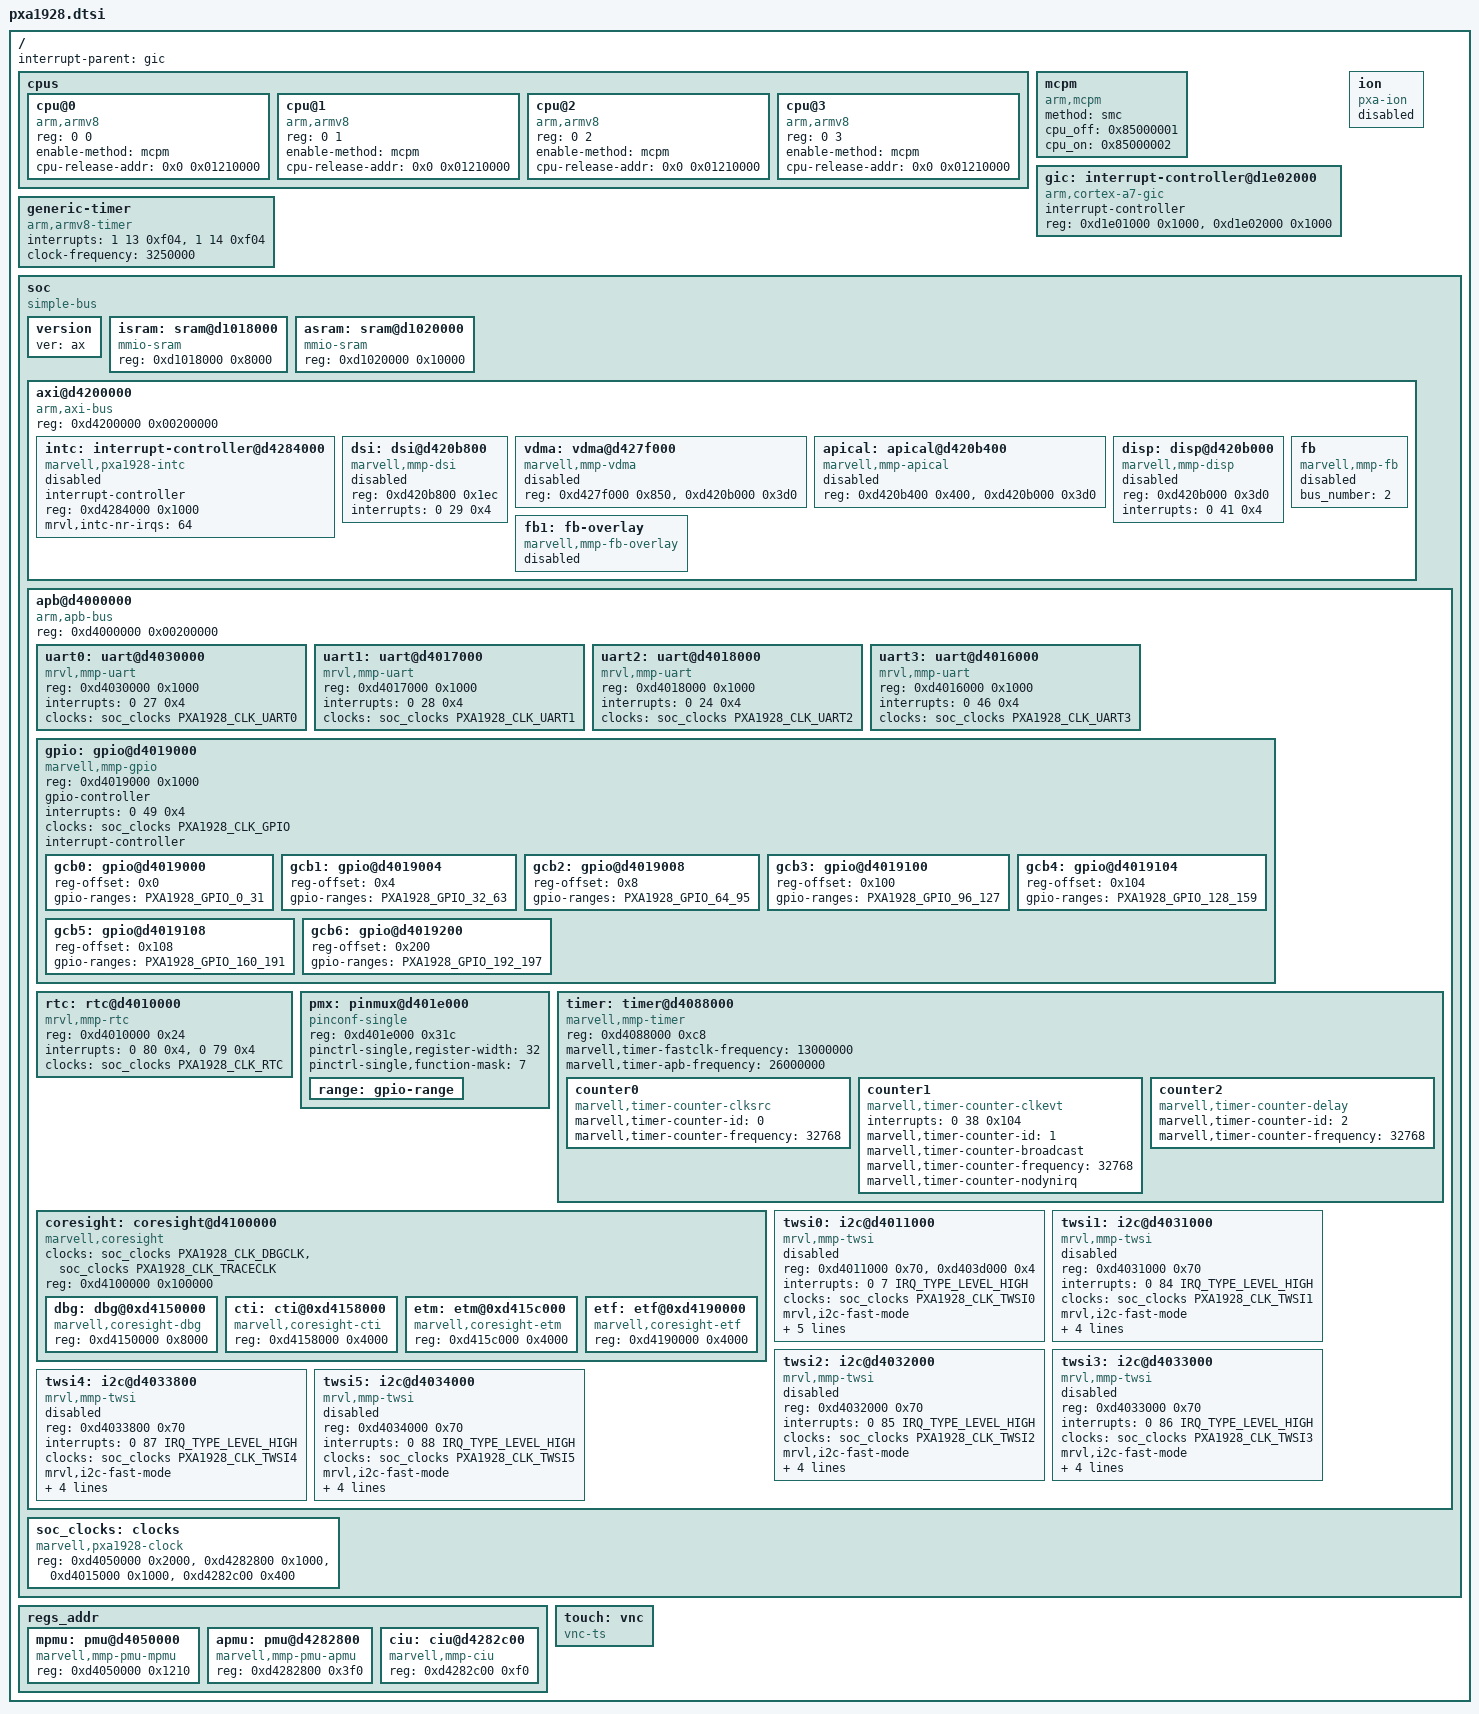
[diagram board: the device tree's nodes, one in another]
/*
 *  Copyright (C) 2013 Marvell Technology Group Ltd.
 *  Author: Chao Xie <chao.xie@marvell.com>
 *
 *  This program is free software; you can redistribute it and/or modify
 *  it under the terms of the GNU General Public License version 2 as
 *  publishhed by the Free Software Foundation.
 */
/memreserve/ 0x01210000 0x8;
#include "pxa1928-pinfunc.h"
#include "../../../../include/dt-bindings/clock/marvell-pxa1928.h"
#include "../../../../include/dt-bindings/interrupt-controller/irq.h"

/ {
	interrupt-parent = <&gic>;
	#address-cells = <1>;
	#size-cells = <1>;

	cpus {
		#address-cells = <2>;
		#size-cells = <0>;

		cpu@0 {
			device_type = "cpu";
			compatible = "arm,armv8";
			reg = <0 0>;
			enable-method = "mcpm";
			cpu-release-addr = <0x0 0x01210000>;
		};
		cpu@1 {
			device_type = "cpu";
			compatible = "arm,armv8";
			reg = <0 1>;
			enable-method = "mcpm";
			cpu-release-addr = <0x0 0x01210000>;
		};
		cpu@2 {
			device_type = "cpu";
			compatible = "arm,armv8";
			reg = <0 2>;
			enable-method = "mcpm";
			cpu-release-addr = <0x0 0x01210000>;
		};
		cpu@3 {
			device_type = "cpu";
			compatible = "arm,armv8";
			reg = <0 3>;
			enable-method = "mcpm";
			cpu-release-addr = <0x0 0x01210000>;
		};
	};

    mcpm {
		compatible      = "arm,mcpm";
		method          = "smc";
		cpu_off		= <0x85000001>;
		cpu_on		= <0x85000002>;
	};

	gic: interrupt-controller@d1e02000 {
		compatible = "arm,cortex-a7-gic";
		interrupt-controller;
		#interrupt-cells = <3>;
		reg = <0xd1e01000 0x1000>,
		      <0xd1e02000 0x1000>;
	};

	generic-timer {
		compatible = "arm,armv8-timer";
		interrupts = <1 13 0xf04>,
		             <1 14 0xf04>;
		clock-frequency = <3250000>;
	};

	ion: ion {
		compatible = "pxa-ion";
		#stream-id-cells = <1>;
		status = "disabled";
	};

	soc {
		#address-cells = <1>;
		#size-cells = <1>;
		compatible = "simple-bus";
		ranges;

		version {
			ver = "ax";
		};

		isram: sram@d1018000 {
			compatible = "mmio-sram";
			reg = <0xd1018000 0x8000>;	/* 32KB */
		};

		asram: sram@d1020000 {
			compatible = "mmio-sram";
			reg = <0xd1020000 0x10000>;	/* 64KB */
		};

		axi@d4200000 {	/* AXI */
			compatible = "arm,axi-bus", "simple-bus";
			#address-cells = <1>;
			#size-cells = <1>;
			reg = <0xd4200000 0x00200000>;
			ranges;

			intc: interrupt-controller@d4284000 {
				compatible = "marvell,pxa1928-intc";
				interrupt-controller;
				#interrupt-cells = <1>;
				reg = <0xd4284000 0x1000>;
				mrvl,intc-nr-irqs = <64>;
				status = "disabled";
			};
			dsi: dsi@d420b800 {
				compatible = "marvell,mmp-dsi";
				reg = <0xd420b800 0x1ec>;
				interrupts = <0 29 0x4>;
				status = "disabled";
			};

			vdma: vdma@d427f000 {
				compatible = "marvell,mmp-vdma";
				reg = <0xd427f000 0x850>, <0xd420b000 0x3d0>;
				status = "disabled";
			};

			apical: apical@d420b400 {
				compatible = "marvell,mmp-apical";
				reg = <0xd420b400 0x400>, <0xd420b000 0x3d0>;
				status = "disabled";
			};

			disp: disp@d420b000 {
				compatible = "marvell,mmp-disp";
				reg = <0xd420b000 0x3d0>;
				interrupts = <0 41 0x4>;
				status = "disabled";
			};

			fb: fb {
				bus_number = <2>;
				compatible = "marvell,mmp-fb";
				status = "disabled";
			};

			fb1: fb-overlay {
				compatible = "marvell,mmp-fb-overlay";
				status = "disabled";
			};
		};

		apb@d4000000 {	/* APB */
			compatible = "arm,apb-bus", "simple-bus";
			#address-cells = <1>;
			#size-cells = <1>;
			reg = <0xd4000000 0x00200000>;
			ranges;

			uart0: uart@d4030000 {
				compatible = "mrvl,mmp-uart";
				reg = <0xd4030000 0x1000>;
				interrupts = <0 27 0x4>;
				clocks = <&soc_clocks PXA1928_CLK_UART0>;
			};

			uart1: uart@d4017000 {
				compatible = "mrvl,mmp-uart";
				reg = <0xd4017000 0x1000>;
				interrupts = <0 28 0x4>;
				clocks = <&soc_clocks PXA1928_CLK_UART1>;
			};

			uart2: uart@d4018000 {
				compatible = "mrvl,mmp-uart";
				reg = <0xd4018000 0x1000>;
				interrupts = <0 24 0x4>;
				clocks = <&soc_clocks PXA1928_CLK_UART2>;
			};

			uart3: uart@d4016000 {
				compatible = "mrvl,mmp-uart";
				reg = <0xd4016000 0x1000>;
				interrupts = <0 46 0x4>;
				clocks = <&soc_clocks PXA1928_CLK_UART3>;
			};

			gpio: gpio@d4019000 {
				compatible = "marvell,mmp-gpio";
				#address-cells = <1>;
				#size-cells = <1>;
				reg = <0xd4019000 0x1000>;
				gpio-controller;
				#gpio-cells = <2>;
				interrupts = <0 49 0x4>;
				clocks = <&soc_clocks PXA1928_CLK_GPIO>;
				interrupt-names = "gpio_mux";
				interrupt-controller;
				#interrupt-cells = <2>;
				ranges;

				gcb0: gpio@d4019000 {
					reg-offset = <0x0>;
					gpio-ranges = <PXA1928_GPIO_0_31>;
				};

				gcb1: gpio@d4019004 {
					reg-offset = <0x4>;
					gpio-ranges = <PXA1928_GPIO_32_63>;
				};

				gcb2: gpio@d4019008 {
					reg-offset = <0x8>;
					gpio-ranges = <PXA1928_GPIO_64_95>;
				};

				gcb3: gpio@d4019100 {
					reg-offset = <0x100>;
					gpio-ranges = <PXA1928_GPIO_96_127>;
				};

				gcb4: gpio@d4019104 {
					reg-offset = <0x104>;
					gpio-ranges = <PXA1928_GPIO_128_159>;
				};

				gcb5: gpio@d4019108 {
					reg-offset = <0x108>;
					gpio-ranges = <PXA1928_GPIO_160_191>;
				};

				gcb6: gpio@d4019200 {
					reg-offset = <0x200>;
					gpio-ranges = <PXA1928_GPIO_192_197>;
				};
			};

			rtc: rtc@d4010000 {
				compatible = "mrvl,mmp-rtc";
				reg = <0xd4010000 0x24>;
				interrupts = <0 80 0x4>,<0 79 0x4>;
				interrupt-names = "rtc 1Hz", "rtc alarm";
				clocks = <&soc_clocks PXA1928_CLK_RTC>;
			};

			pmx: pinmux@d401e000 {
				compatible = "pinconf-single";
				reg = <0xd401e000 0x31c>;
				#address-cells = <1>;
				#size-cells = <1>;
				#gpio-range-cells = <3>;
				ranges;

				pinctrl-single,register-width = <32>;
				pinctrl-single,function-mask = <7>;

				range: gpio-range {
					#pinctrl-single,gpio-range-cells = <3>;
				};
			};

			timer: timer@d4088000 {
				compatible = "marvell,mmp-timer";
				reg = <0xd4088000 0xc8>;
				marvell,timer-fastclk-frequency = <13000000>;
				marvell,timer-apb-frequency = <26000000>;

				counter0 {
					compatible = "marvell,timer-counter-clksrc";
					marvell,timer-counter-id = <0>;
					marvell,timer-counter-frequency = <32768>;
				};

				counter1 {
					compatible = "marvell,timer-counter-clkevt";
					interrupts = <0 38 0x104>;
					marvell,timer-counter-id = <1>;
					marvell,timer-counter-broadcast;
					marvell,timer-counter-frequency = <32768>;
					marvell,timer-counter-nodynirq;
				};

				counter2 {
					compatible = "marvell,timer-counter-delay";
					marvell,timer-counter-id = <2>;
					marvell,timer-counter-frequency = <32768>;
				};
			};

			coresight: coresight@d4100000 {
				compatible = "marvell,coresight";
				clocks = <&soc_clocks PXA1928_CLK_DBGCLK>,
					 <&soc_clocks PXA1928_CLK_TRACECLK>;
				clock-names = "DBGCLK","TRACECLK";
				#address-cells = <1>;
				#size-cells = <1>;
				reg = <0xd4100000 0x100000>;
				ranges;

				dbg: dbg@0xd4150000 {
					compatible = "marvell,coresight-dbg";
					reg = <0xd4150000 0x8000>;
				};

				cti: cti@0xd4158000 {
					compatible = "marvell,coresight-cti";
				        reg = <0xd4158000 0x4000>;
				};

				etm: etm@0xd415c000 {
					compatible = "marvell,coresight-etm";
				        reg = <0xd415c000 0x4000>;
				};

				etf: etf@0xd4190000 {
					compatible = "marvell,coresight-etf";
				        reg = <0xd4190000 0x4000>;
				};
			};

			twsi0: i2c@d4011000 {
				compatible = "mrvl,mmp-twsi";
				#address-cells = <1>;
				#size-cells = <0>;

				/* RIPC */
				reg = <0xd4011000 0x70>,
				      <0xd403d000 0x4>;
				interrupts = <0 7 IRQ_TYPE_LEVEL_HIGH>;
				clocks = <&soc_clocks PXA1928_CLK_TWSI0>;

				mrvl,i2c-fast-mode;
				/*
				 *ilcr: fast mode b17~9=0x1a, 380k
				 *      standard mode b8~0=0x7e, 100k
				 *iwcr: b5~0=b01010 recommended value from spec
				 */
				marvell,i2c-ilcr = <0x082c347e>;
				marvell,i2c-iwcr = <0x0000142a>;
				marvell,i2c-always-on;

				marvell,i2c-enable-bus-rst;
				marvell,i2c-gpio-bus-rst;

				status = "disabled";
			};

			twsi1: i2c@d4031000 {
				compatible = "mrvl,mmp-twsi";
				#address-cells = <1>;
				#size-cells = <0>;

				reg = <0xd4031000 0x70>;
				interrupts = <0 84 IRQ_TYPE_LEVEL_HIGH>;
				clocks = <&soc_clocks PXA1928_CLK_TWSI1>;

				mrvl,i2c-fast-mode;
				marvell,i2c-ilcr = <0x082c347e>;
				marvell,i2c-iwcr = <0x0000142a>;
				marvell,i2c-enable-bus-rst;
				marvell,i2c-gpio-bus-rst;

				status = "disabled";
			};

			twsi2: i2c@d4032000 {
				compatible = "mrvl,mmp-twsi";
				#address-cells = <1>;
				#size-cells = <0>;

				reg = <0xd4032000 0x70>;
				interrupts = <0 85 IRQ_TYPE_LEVEL_HIGH>;
				clocks = <&soc_clocks PXA1928_CLK_TWSI2>;

				mrvl,i2c-fast-mode;
				marvell,i2c-ilcr = <0x082c347e>;
				marvell,i2c-iwcr = <0x0000142a>;
				marvell,i2c-enable-bus-rst;
				marvell,i2c-gpio-bus-rst;

				status = "disabled";
			};

			twsi3: i2c@d4033000 {
				compatible = "mrvl,mmp-twsi";
				#address-cells = <1>;
				#size-cells = <0>;

				reg = <0xd4033000 0x70>;
				interrupts = <0 86 IRQ_TYPE_LEVEL_HIGH>;
				clocks = <&soc_clocks PXA1928_CLK_TWSI3>;

				mrvl,i2c-fast-mode;
				marvell,i2c-ilcr = <0x082c347e>;
				marvell,i2c-iwcr = <0x0000142a>;
				marvell,i2c-enable-bus-rst;
				marvell,i2c-gpio-bus-rst;

				status = "disabled";
			};

			twsi4: i2c@d4033800 {
				compatible = "mrvl,mmp-twsi";
				#address-cells = <1>;
				#size-cells = <0>;

				reg = <0xd4033800 0x70>;
				interrupts = <0 87 IRQ_TYPE_LEVEL_HIGH>;
				clocks = <&soc_clocks PXA1928_CLK_TWSI4>;

				mrvl,i2c-fast-mode;
				marvell,i2c-ilcr = <0x082c347e>;
				marvell,i2c-iwcr = <0x0000142a>;
				marvell,i2c-enable-bus-rst;
				marvell,i2c-gpio-bus-rst;

				status = "disabled";
			};
			twsi5: i2c@d4034000 {
				compatible = "mrvl,mmp-twsi";
				#address-cells = <1>;
				#size-cells = <0>;

				reg = <0xd4034000 0x70>;
				interrupts = <0 88 IRQ_TYPE_LEVEL_HIGH>;
				clocks = <&soc_clocks PXA1928_CLK_TWSI5>;

				mrvl,i2c-fast-mode;
				marvell,i2c-ilcr = <0x082c347e>;
				marvell,i2c-iwcr = <0x0000142a>;
				marvell,i2c-enable-bus-rst;
				marvell,i2c-gpio-bus-rst;

				status = "disabled";
			};
		};

		soc_clocks: clocks{
			compatible = "marvell,pxa1928-clock";
			reg = <0xd4050000 0x2000>,
			      <0xd4282800 0x1000>,
			      <0xd4015000 0x1000>,
			      <0xd4282c00 0x400>;
			reg-names = "mpmu", "apmu", "apbc", "ciu";
			#clock-cells = <1>;
	        };
	};

	regs_addr {
		#address-cells = <1>;
		#size-cells = <1>;
		ranges;

		mpmu: pmu@d4050000 {
			compatible = "marvell,mmp-pmu-mpmu";
			reg = <0xd4050000 0x1210>;
		};

		apmu: pmu@d4282800 {
			compatible = "marvell,mmp-pmu-apmu";
			reg = <0xd4282800 0x3f0>;
		};

		ciu: ciu@d4282c00 {
			compatible = "marvell,mmp-ciu";
			reg = <0xd4282c00 0xf0>;
		};
	};

	touch: vnc {
		compatible = "vnc-ts";
	};
};
